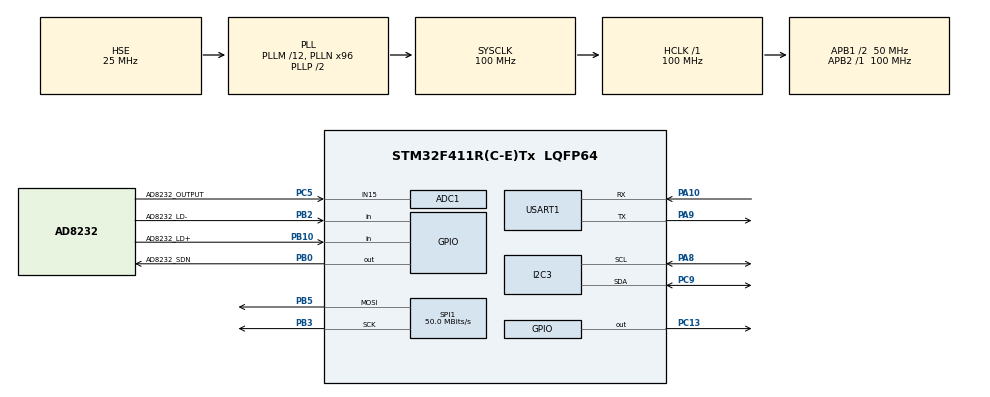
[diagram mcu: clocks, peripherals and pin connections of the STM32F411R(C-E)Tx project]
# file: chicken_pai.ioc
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ADC1.Channel-0\#ChannelRegularConversion=ADC_CHANNEL_15
ADC1.NbrOfConversionFlag=1
ADC1.Rank-0\#ChannelRegularConversion=1
ADC1.SamplingTime-0\#ChannelRegularConversion=ADC_SAMPLETIME_3CYCLES
ADC1.master=1
Dma.Request0=SPI1_TX
Dma.SPI1_TX.0.Direction=DMA_MEMORY_TO_PERIPH
Dma.SPI1_TX.0.FIFOMode=DMA_FIFOMODE_DISABLE
Dma.SPI1_TX.0.Instance=DMA2_Stream2
Dma.SPI1_TX.0.MemDataAlignment=DMA_MDATAALIGN_BYTE
Dma.SPI1_TX.0.MemInc=DMA_MINC_ENABLE
Dma.SPI1_TX.0.Mode=DMA_NORMAL
Dma.SPI1_TX.0.PeriphDataAlignment=DMA_PDATAALIGN_BYTE
Dma.SPI1_TX.0.PeriphInc=DMA_PINC_DISABLE
Dma.SPI1_TX.0.Priority=DMA_PRIORITY_LOW
FREERTOS.Tasks01=defaultTask,24,512,mytask,As weak,NULL,Dynamic,NULL,NULL;ADCTask,8,128,ADC_Task,As weak,NULL,Dynamic,NULL,NULL
FREERTOS.configENABLE_FPU=0
FREERTOS.configTOTAL_HEAP_SIZE=32768
FREERTOS.configUSE_NEWLIB_REENTRANT=0
FREERTOS.configUSE_TICK_HOOK=1
I2C3.I2C_Mode=I2C_Fast
Mcu.Family=STM32F4
Mcu.Name=STM32F411R(C-E)Tx
Mcu.Package=LQFP64
NVIC.DMA2_Stream2_IRQn=true\:5\:0\:false\:false\:true\:true\:false\:true\:true
NVIC.PriorityGroup=NVIC_PRIORITYGROUP_4
NVIC.TIM1_BRK_TIM9_IRQn=true\:15\:0\:false\:false\:true\:false\:false\:true\:true
NVIC.TIM3_IRQn=true\:5\:0\:false\:false\:false\:true\:true\:true\:true
NVIC.TimeBase=TIM1_BRK_TIM9_IRQn
NVIC.TimeBaseIP=TIM9
PA10.Mode=Asynchronous
PA10.Signal=USART1_RX
PA13.Mode=Serial_Wire
PA13.Signal=SYS_JTMS-SWDIO
PA14.Mode=Serial_Wire
PA14.Signal=SYS_JTCK-SWCLK
PA8.Mode=I2C
PA8.Signal=I2C3_SCL
PA9.Mode=Asynchronous
PA9.Signal=USART1_TX
PB0.GPIO_Label=AD8232_SDN
PB0.GPIO_PuPd=GPIO_PULLUP
PB0.GPIO_Speed=GPIO_SPEED_FREQ_HIGH
PB0.PinState=GPIO_PIN_RESET
PB0.Signal=GPIO_Output
PB10.GPIO_Label=AD8232_LD+
PB10.GPIO_PuPd=GPIO_NOPULL
PB10.Signal=GPIO_Input
PB2.GPIO_Label=AD8232_LD-
PB2.GPIO_PuPd=GPIO_NOPULL
PB2.Signal=GPIO_Input
PB3.Mode=TX_Only_Simplex_Unidirect_Master
PB3.Signal=SPI1_SCK
PB5.Mode=TX_Only_Simplex_Unidirect_Master
PB5.Signal=SPI1_MOSI
PC13-ANTI_TAMP.GPIO_PuPd=GPIO_NOPULL
PC13-ANTI_TAMP.PinState=GPIO_PIN_RESET
PC13-ANTI_TAMP.Signal=GPIO_Output
PC14-OSC32_IN.Mode=LSE-External-Oscillator
PC14-OSC32_IN.Signal=RCC_OSC32_IN
PC15-OSC32_OUT.Mode=LSE-External-Oscillator
PC15-OSC32_OUT.Signal=RCC_OSC32_OUT
PC5.GPIO_Label=AD8232_OUTPUT
PC5.Signal=ADCx_IN15
PC9.Mode=I2C
PC9.Signal=I2C3_SDA
PH0\ -\ OSC_IN.Mode=HSE-External-Oscillator
PH0\ -\ OSC_IN.Signal=RCC_OSC_IN
PH1\ -\ OSC_OUT.Mode=HSE-External-Oscillator
PH1\ -\ OSC_OUT.Signal=RCC_OSC_OUT
ProjectManager.HeapSize=0x400
ProjectManager.StackSize=0xE00
ProjectManager.TargetToolchain=MDK-ARM V5.32
RCC.48MHZClocksFreq_Value=50000000
RCC.AHBFreq_Value=100000000
RCC.APB1CLKDivider=RCC_HCLK_DIV2
RCC.APB1Freq_Value=50000000
RCC.APB1TimFreq_Value=100000000
RCC.APB2Freq_Value=100000000
RCC.APB2TimFreq_Value=100000000
RCC.CortexFreq_Value=100000000
RCC.HCLKFreq_Value=100000000
RCC.HSE_VALUE=25000000
RCC.HSI_VALUE=16000000
RCC.PLLM=12
RCC.PLLN=96
RCC.PLLSourceVirtual=RCC_PLLSOURCE_HSE
RCC.SYSCLKFreq_VALUE=100000000
RCC.SYSCLKSource=RCC_SYSCLKSOURCE_PLLCLK
RCC.VCOOutputFreq_Value=200000000
SH.ADCx_IN15.0=ADC1_IN15,IN15
SPI1.CLKPhase=SPI_PHASE_2EDGE
SPI1.CLKPolarity=SPI_POLARITY_HIGH
SPI1.CalculateBaudRate=50.0 MBits/s
SPI1.Direction=SPI_DIRECTION_2LINES
SPI1.Mode=SPI_MODE_MASTER
SPI1.VirtualType=VM_MASTER
TIM3.Period=1000-1
TIM3.Prescaler=100-1
USART1.VirtualMode=VM_ASYNC
VP_FREERTOS_VS_CMSIS_V2.Mode=CMSIS_V2
VP_SYS_VS_tim9.Mode=TIM9
VP_TIM3_VS_ClockSourceINT.Mode=Internal
board=custom

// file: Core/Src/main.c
/* USER CODE BEGIN Header */
/**
  ******************************************************************************
  * @file           : main.c
  * @brief          : Main program body
  ******************************************************************************
  * @attention
  *
  * Copyright (c) 2024 STMicroelectronics.
  * All rights reserved.
  *
  * This software is licensed under terms that can be found in the LICENSE file
  * in the root directory of this software component.
  * If no LICENSE file comes with this software, it is provided AS-IS.
  *
  ******************************************************************************
  */
/* USER CODE END Header */
#include "main.h"
#include "cmsis_os.h"
#include "adc.h"
#include "dma.h"
#include "i2c.h"
#include "spi.h"
#include "tim.h"
#include "usart.h"
#include "gpio.h"

void SystemClock_Config(void);
void MX_FREERTOS_Init(void);

int main(void)
{

  /* MCU Configuration--------------------------------------------------------*/

  /* Reset of all peripherals, Initializes the Flash interface and the Systick. */
  HAL_Init();

  /* Configure the system clock */
  SystemClock_Config();

  /* Initialize all configured peripherals */
  MX_GPIO_Init();
  MX_DMA_Init();
  MX_USART1_UART_Init();
  MX_SPI1_Init();
  MX_I2C3_Init();
  MX_TIM3_Init();
  MX_ADC1_Init();

  /* Init scheduler */
  osKernelInitialize();

  /* Call init function for freertos objects (in cmsis_os2.c) */
  MX_FREERTOS_Init();

  /* Start scheduler */
  osKernelStart();

  /* We should never get here as control is now taken by the scheduler */

  /* Infinite loop */
  while (1)
  {

  }
}

void SystemClock_Config(void)
{
  RCC_OscInitTypeDef RCC_OscInitStruct = {0};
  RCC_ClkInitTypeDef RCC_ClkInitStruct = {0};

  /** Configure the main internal regulator output voltage
  */
  __HAL_RCC_PWR_CLK_ENABLE();
  __HAL_PWR_VOLTAGESCALING_CONFIG(PWR_REGULATOR_VOLTAGE_SCALE1);

  /** Initializes the RCC Oscillators according to the specified parameters
  * in the RCC_OscInitTypeDef structure.
  */
  RCC_OscInitStruct.OscillatorType = RCC_OSCILLATORTYPE_HSE;
  RCC_OscInitStruct.HSEState = RCC_HSE_ON;
  RCC_OscInitStruct.PLL.PLLState = RCC_PLL_ON;
  RCC_OscInitStruct.PLL.PLLSource = RCC_PLLSOURCE_HSE;
  RCC_OscInitStruct.PLL.PLLM = 12;
  RCC_OscInitStruct.PLL.PLLN = 96;
  RCC_OscInitStruct.PLL.PLLP = RCC_PLLP_DIV2;
  RCC_OscInitStruct.PLL.PLLQ = 4;
  if (HAL_RCC_OscConfig(&RCC_OscInitStruct) != HAL_OK)
  {
    Error_Handler();
  }

  /** Initializes the CPU, AHB and APB buses clocks
  */
  RCC_ClkInitStruct.ClockType = RCC_CLOCKTYPE_HCLK|RCC_CLOCKTYPE_SYSCLK
                              |RCC_CLOCKTYPE_PCLK1|RCC_CLOCKTYPE_PCLK2;
  RCC_ClkInitStruct.SYSCLKSource = RCC_SYSCLKSOURCE_PLLCLK;
  RCC_ClkInitStruct.AHBCLKDivider = RCC_SYSCLK_DIV1;
  RCC_ClkInitStruct.APB1CLKDivider = RCC_HCLK_DIV2;
  RCC_ClkInitStruct.APB2CLKDivider = RCC_HCLK_DIV1;

  if (HAL_RCC_ClockConfig(&RCC_ClkInitStruct, FLASH_LATENCY_3) != HAL_OK)
  {
    Error_Handler();
  }
}

/* USER CODE BEGIN 4 */

//定时器3中断服务程序
void TIM3_IRQHandler(void)
{
    HAL_TIM_IRQHandler(&htim3); // 调用HAL库的中断处理函数

}

/* USER CODE END 4 */

void HAL_TIM_PeriodElapsedCallback(TIM_HandleTypeDef *htim)
{
  if (htim->Instance == TIM9) {
    HAL_IncTick();
  }
}

void Error_Handler(void)
{
  __disable_irq();
  while (1)
  {
  }
}

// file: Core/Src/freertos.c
/* USER CODE BEGIN Header */
/**
  ******************************************************************************
  * File Name          : freertos.c
  * Description        : Code for freertos applications
  ******************************************************************************
  * @attention
  *
  * Copyright (c) 2024 STMicroelectronics.
  * All rights reserved.
  *
  * This software is licensed under terms that can be found in the LICENSE file
  * in the root directory of this software component.
  * If no LICENSE file comes with this software, it is provided AS-IS.
  *
  ******************************************************************************
  */
/* USER CODE END Header */

#include "FreeRTOS.h"
#include "task.h"
#include "main.h"
#include "cmsis_os.h"

/* Definitions for defaultTask */
osThreadId_t defaultTaskHandle;
const osThreadAttr_t defaultTask_attributes = {
  .name = "defaultTask",
  .stack_size = 512 * 4,
  .priority = (osPriority_t) osPriorityNormal,
};
/* Definitions for ADCTask */
osThreadId_t ADCTaskHandle;
const osThreadAttr_t ADCTask_attributes = {
  .name = "ADCTask",
  .stack_size = 128 * 4,
  .priority = (osPriority_t) osPriorityLow,
};

void mytask(void *argument);
void ADC_Task(void *argument);

void MX_FREERTOS_Init(void); /* (MISRA C 2004 rule 8.1) */

/* Hook prototypes */
void vApplicationTickHook(void);

void MX_FREERTOS_Init(void) {

  /* Create the thread(s) */
  /* creation of defaultTask */
  defaultTaskHandle = osThreadNew(mytask, NULL, &defaultTask_attributes);

  /* creation of ADCTask */
  ADCTaskHandle = osThreadNew(ADC_Task, NULL, &ADCTask_attributes);

}

__weak void mytask(void *argument)
{
  for(;;)
  {
    osDelay(1);
  }
}

__weak void ADC_Task(void *argument)
{
  for(;;)
  {
    osDelay(1);
  }
}
